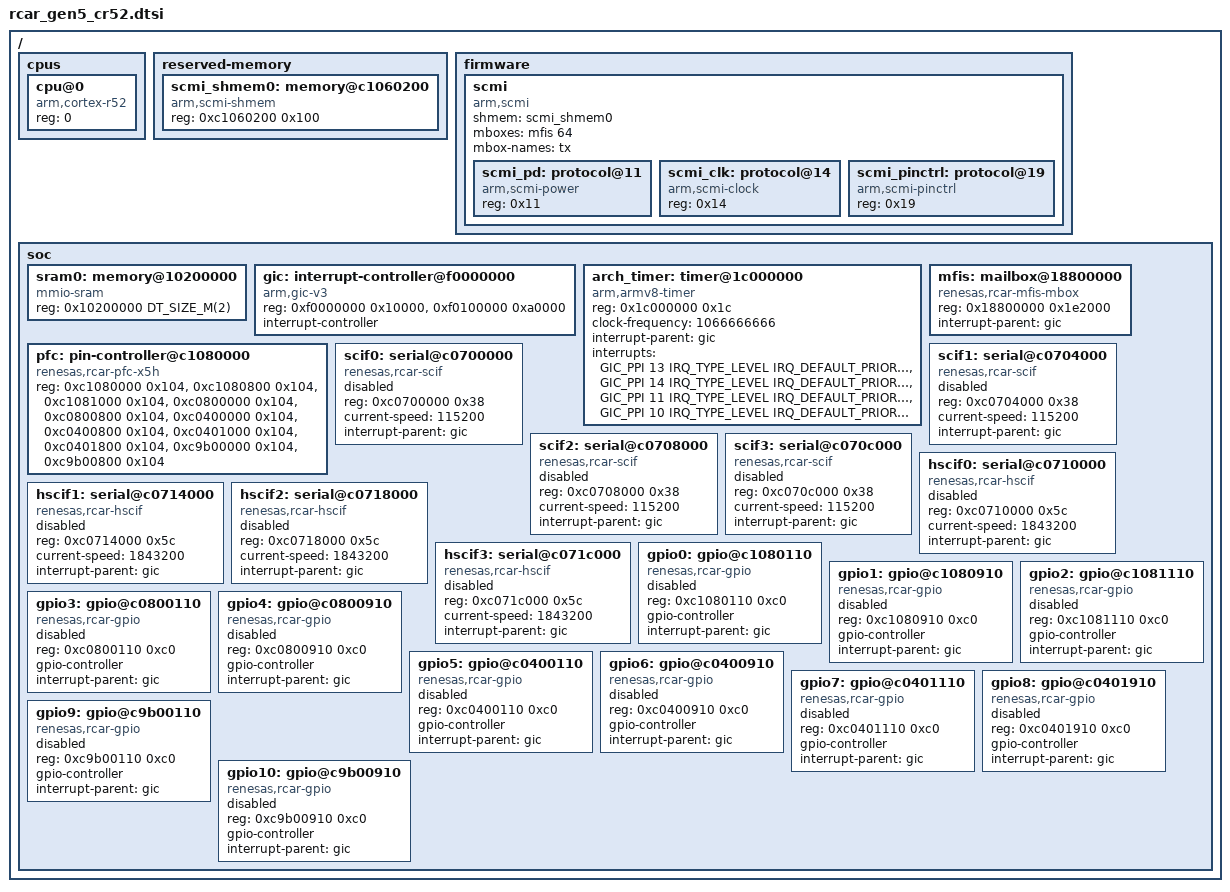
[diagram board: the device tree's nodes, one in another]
/*
 * Copyright (c) 2026 BayLibre, SAS
 *
 * SPDX-License-Identifier: Apache-2.0
 */

#include <mem.h>
#include <arm/armv8-r.dtsi>
#include <zephyr/dt-bindings/interrupt-controller/arm-gic.h>
#include <zephyr/dt-bindings/gpio/gpio.h>

/ {
	cpus {
		#address-cells = <1>;
		#size-cells = <0>;

		cpu@0 {
			device_type = "cpu";
			compatible = "arm,cortex-r52";
			reg = <0>;
		};
	};

	reserved-memory {
		#address-cells = <1>;
		#size-cells = <1>;

		scmi_shmem0: memory@c1060200 {
			compatible = "arm,scmi-shmem";
			reg = <0xc1060200 0x100>;
		};
	};

	firmware {
		scmi {
			compatible = "arm,scmi";
			shmem = <&scmi_shmem0>;
			mboxes = <&mfis 64>;
			mbox-names = "tx";

			#address-cells = <1>;
			#size-cells = <0>;

			scmi_pd: protocol@11 {
				compatible = "arm,scmi-power";
				reg = <0x11>;
				#power-domain-cells = <1>;
			};

			scmi_clk: protocol@14 {
				compatible = "arm,scmi-clock";
				reg = <0x14>;
				#clock-cells = <1>;
			};

			scmi_pinctrl: protocol@19 {
				compatible = "arm,scmi-pinctrl";
				reg = <0x19>;
			};
		};
	};

	soc {
		sram0: memory@10200000 {
			compatible = "mmio-sram";
			reg = <0x10200000 DT_SIZE_M(2)>;
		};

		gic: interrupt-controller@f0000000 {
			compatible = "arm,gic-v3", "arm,gic";
			reg = <0xf0000000 0x10000>, /* GICD */
			      <0xf0100000 0xa0000>; /* GICR */
			interrupt-controller;
			#interrupt-cells = <4>;
			status = "okay";
		};

		arch_timer: timer@1c000000 {
			compatible = "arm,armv8-timer";
			reg = <0x1c000000 0x1c>;
			clock-frequency = <1066666666>;
			interrupt-parent = <&gic>;
			interrupts = <GIC_PPI 13 IRQ_TYPE_LEVEL IRQ_DEFAULT_PRIORITY>,
				     <GIC_PPI 14 IRQ_TYPE_LEVEL IRQ_DEFAULT_PRIORITY>,
				     <GIC_PPI 11 IRQ_TYPE_LEVEL IRQ_DEFAULT_PRIORITY>,
				     <GIC_PPI 10 IRQ_TYPE_LEVEL IRQ_DEFAULT_PRIORITY>;
		};

		mfis: mailbox@18800000 {
			compatible = "renesas,rcar-mfis-mbox";
			reg = <0x18800000 0x1e2000>;
			interrupt-parent = <&gic>;
			#mbox-cells = <1>;
		};

		pfc: pin-controller@c1080000 {
			compatible = "renesas,rcar-pfc-x5h";
			reg = <0xc1080000 0x104>, <0xc1080800 0x104>,
			      <0xc1081000 0x104>, <0xc0800000 0x104>,
			      <0xc0800800 0x104>, <0xc0400000 0x104>,
			      <0xc0400800 0x104>, <0xc0401000 0x104>,
			      <0xc0401800 0x104>, <0xc9b00000 0x104>,
			      <0xc9b00800 0x104>;
		};

		scif0: serial@c0700000 {
			compatible = "renesas,rcar-scif";
			reg = <0xc0700000 0x38>;
			current-speed = <115200>;
			interrupt-parent = <&gic>;
			status = "disabled";
		};

		scif1: serial@c0704000 {
			compatible = "renesas,rcar-scif";
			reg = <0xc0704000 0x38>;
			current-speed = <115200>;
			interrupt-parent = <&gic>;
			status = "disabled";
		};

		scif2: serial@c0708000 {
			compatible = "renesas,rcar-scif";
			reg = <0xc0708000 0x38>;
			current-speed = <115200>;
			interrupt-parent = <&gic>;
			status = "disabled";
		};

		scif3: serial@c070c000 {
			compatible = "renesas,rcar-scif";
			reg = <0xc070c000 0x38>;
			current-speed = <115200>;
			interrupt-parent = <&gic>;
			status = "disabled";
		};

		hscif0: serial@c0710000 {
			compatible = "renesas,rcar-hscif";
			reg = <0xc0710000 0x5c>;
			current-speed = <1843200>;
			interrupt-parent = <&gic>;
			status = "disabled";
		};

		hscif1: serial@c0714000 {
			compatible = "renesas,rcar-hscif";
			reg = <0xc0714000 0x5c>;
			current-speed = <1843200>;
			interrupt-parent = <&gic>;
			status = "disabled";
		};

		hscif2: serial@c0718000 {
			compatible = "renesas,rcar-hscif";
			reg = <0xc0718000 0x5c>;
			current-speed = <1843200>;
			interrupt-parent = <&gic>;
			status = "disabled";
		};

		hscif3: serial@c071c000 {
			compatible = "renesas,rcar-hscif";
			reg = <0xc071c000 0x5c>;
			current-speed = <1843200>;
			interrupt-parent = <&gic>;
			status = "disabled";
		};

		gpio0: gpio@c1080110 {
			compatible = "renesas,rcar-gpio";
			reg = <0xc1080110 0xc0>;
			#gpio-cells = <2>;
			gpio-controller;
			interrupt-parent = <&gic>;
			status = "disabled";
		};

		gpio1: gpio@c1080910 {
			compatible = "renesas,rcar-gpio";
			reg = <0xc1080910 0xc0>;
			#gpio-cells = <2>;
			gpio-controller;
			interrupt-parent = <&gic>;
			status = "disabled";
		};

		gpio2: gpio@c1081110 {
			compatible = "renesas,rcar-gpio";
			reg = <0xc1081110 0xc0>;
			#gpio-cells = <2>;
			gpio-controller;
			interrupt-parent = <&gic>;
			status = "disabled";
		};

		gpio3: gpio@c0800110 {
			compatible = "renesas,rcar-gpio";
			reg = <0xc0800110 0xc0>;
			#gpio-cells = <2>;
			gpio-controller;
			interrupt-parent = <&gic>;
			status = "disabled";
		};

		gpio4: gpio@c0800910 {
			compatible = "renesas,rcar-gpio";
			reg = <0xc0800910 0xc0>;
			#gpio-cells = <2>;
			gpio-controller;
			interrupt-parent = <&gic>;
			status = "disabled";
		};

		gpio5: gpio@c0400110 {
			compatible = "renesas,rcar-gpio";
			reg = <0xc0400110 0xc0>;
			#gpio-cells = <2>;
			gpio-controller;
			interrupt-parent = <&gic>;
			status = "disabled";
		};

		gpio6: gpio@c0400910 {
			compatible = "renesas,rcar-gpio";
			reg = <0xc0400910 0xc0>;
			#gpio-cells = <2>;
			gpio-controller;
			interrupt-parent = <&gic>;
			status = "disabled";
		};

		gpio7: gpio@c0401110 {
			compatible = "renesas,rcar-gpio";
			reg = <0xc0401110 0xc0>;
			#gpio-cells = <2>;
			gpio-controller;
			interrupt-parent = <&gic>;
			status = "disabled";
		};

		gpio8: gpio@c0401910 {
			compatible = "renesas,rcar-gpio";
			reg = <0xc0401910 0xc0>;
			#gpio-cells = <2>;
			gpio-controller;
			interrupt-parent = <&gic>;
			status = "disabled";
		};

		gpio9: gpio@c9b00110 {
			compatible = "renesas,rcar-gpio";
			reg = <0xc9b00110 0xc0>;
			#gpio-cells = <2>;
			gpio-controller;
			interrupt-parent = <&gic>;
			status = "disabled";
		};

		gpio10: gpio@c9b00910 {
			compatible = "renesas,rcar-gpio";
			reg = <0xc9b00910 0xc0>;
			#gpio-cells = <2>;
			gpio-controller;
			interrupt-parent = <&gic>;
			status = "disabled";
		};
	};
};
